# UFS0_HCLK_ECC_AGGR_CFG register map
Vendor: Texas Instruments
Peripheral module from a debugger description file (folder J7ES).
Registers are 32-bit, access not given, reset 0x0 unless marked. A register's access mark holds for its fields unless they carry their own. Offsets are as the file gives them; lines under a group give offsets from that group; [hi:lo] are bit positions; {n}, {i} and the like mark numbered series; 'fields as' and 'values as' point back to an identical list; <NAME> marks a mode.

## UFS0_HCLK_ECC_AGGR_CFG
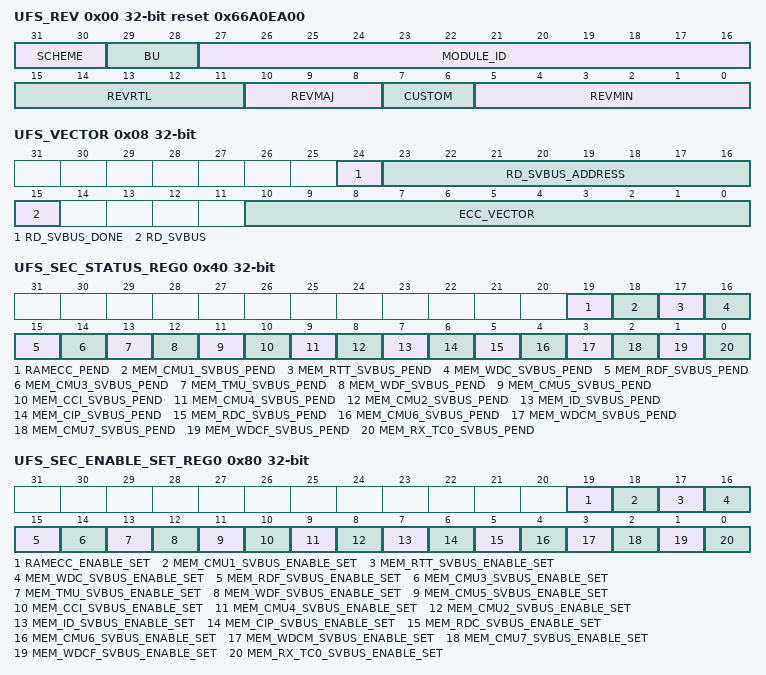
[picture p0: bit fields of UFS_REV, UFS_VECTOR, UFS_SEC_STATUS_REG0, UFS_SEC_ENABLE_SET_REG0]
0x00 UFS_REV ro reset 0x66A0EA00 — Aggregator Revision Register Revision parameters.
  [31:30] SCHEME
  [29:28] BU — Business Unit
  [27:16] MODULE_ID
  [15:11] REVRTL — RTL Version
  [10:8] REVMAJ — Major Version
  [7:6] CUSTOM — Custom Version
  [5:0] REVMIN — Minor Version
0x08 UFS_VECTOR — ECC Vector Register
  [24] RD_SVBUS_DONE — Read Done Status to indicate if read on the serial VBUS interface is complete, write of any value will clear this bit. (access RW1C)
  [23:16] RD_SVBUS_ADDRESS rw — Read Address
  [15] RD_SVBUS — Read Trigger Write 1h to trigger a read on the serial VBUS interface. (access RW1S)
  [10:0] ECC_VECTOR rw — ECC RAM ID Value written to select the corresponding ECC RAM for control or status.
0x0C UFS_STAT ro reset 0x14 — Misc Status Register
  [10:0] NUM_RAMS — Number of RAMs Indicates the number of RAMS serviced by the ECC Aggregator.
0x10 UFS_RESERVED_SVBUS_y rw — Reserved Area For Serial VBUS Registers Offset = 10h + (y × 4h); where y = 0h to 7h;
  [31:0] DATA — Serial VBUS Register Data
0x3C UFS_SEC_EOI_REG — SEC End Of Interrupt (EOI) Register The SEC End Of Interrupt (EOI) register is used to re-trigger the pulse interrupt signal to ensure that any nested interrupt events are serviced. The software interrupt handler must write to the SEC End Of Interrupt (EOI) register at the end of the current interrupt processing routine, so that new events can re-trigger the pulse interrupt signal again. For level interrupt signals the SEC End Of Interrupt (EOI) register is not functional and must not be used.
  [0] EOI_WR — End Of Interrupt (EOI) (access RW1S)
0x40 UFS_SEC_STATUS_REG0 — SEC Interrupt Status Register 0
  [19] RAMECC_PEND — Interrupt Pending Status for ramecc_pend (access RW1S)
  [18] MEM_CMU1_SVBUS_PEND — Interrupt Pending Status for mem_cmu1_svbus_pend (access RW1S)
  [17] MEM_RTT_SVBUS_PEND — Interrupt Pending Status for mem_rtt_svbus_pend (access RW1S)
  [16] MEM_WDC_SVBUS_PEND — Interrupt Pending Status for mem_wdc_svbus_pend (access RW1S)
  [15] MEM_RDF_SVBUS_PEND — Interrupt Pending Status for mem_rdf_svbus_pend (access RW1S)
  [14] MEM_CMU3_SVBUS_PEND — Interrupt Pending Status for mem_cmu3_svbus_pend (access RW1S)
  [13] MEM_TMU_SVBUS_PEND — Interrupt Pending Status for mem_tmu_svbus_pend (access RW1S)
  [12] MEM_WDF_SVBUS_PEND — Interrupt Pending Status for mem_wdf_svbus_pend (access RW1S)
  [11] MEM_CMU5_SVBUS_PEND — Interrupt Pending Status for mem_cmu5_svbus_pend (access RW1S)
  [10] MEM_CCI_SVBUS_PEND — Interrupt Pending Status for mem_cci_svbus_pend (access RW1S)
  [9] MEM_CMU4_SVBUS_PEND — Interrupt Pending Status for mem_cmu4_svbus_pend (access RW1S)
  [8] MEM_CMU2_SVBUS_PEND — Interrupt Pending Status for mem_cmu2_svbus_pend (access RW1S)
  [7] MEM_ID_SVBUS_PEND — Interrupt Pending Status for mem_id_svbus_pend (access RW1S)
  [6] MEM_CIP_SVBUS_PEND — Interrupt Pending Status for mem_cip_svbus_pend (access RW1S)
  [5] MEM_RDC_SVBUS_PEND — Interrupt Pending Status for mem_rdc_svbus_pend (access RW1S)
  [4] MEM_CMU6_SVBUS_PEND — Interrupt Pending Status for mem_cmu6_svbus_pend (access RW1S)
  [3] MEM_WDCM_SVBUS_PEND — Interrupt Pending Status for mem_wdcm_svbus_pend (access RW1S)
  [2] MEM_CMU7_SVBUS_PEND — Interrupt Pending Status for mem_cmu7_svbus_pend (access RW1S)
  [1] MEM_WDCF_SVBUS_PEND — Interrupt Pending Status for mem_wdcf_svbus_pend (access RW1S)
  [0] MEM_RX_TC0_SVBUS_PEND — Interrupt Pending Status for mem_rx_tc0_svbus_pend (access RW1S)
0x80 UFS_SEC_ENABLE_SET_REG0 — SEC Interrupt Enable Set Register 0
  [19] RAMECC_ENABLE_SET — Interrupt Enable Set for ramecc_pend (access RW1S)
  [18] MEM_CMU1_SVBUS_ENABLE_SET — Interrupt Enable Set for mem_cmu1_svbus_pend (access RW1S)
  [17] MEM_RTT_SVBUS_ENABLE_SET — Interrupt Enable Set for mem_rtt_svbus_pend (access RW1S)
  [16] MEM_WDC_SVBUS_ENABLE_SET — Interrupt Enable Set for mem_wdc_svbus_pend (access RW1S)
  [15] MEM_RDF_SVBUS_ENABLE_SET — Interrupt Enable Set for mem_rdf_svbus_pend (access RW1S)
  [14] MEM_CMU3_SVBUS_ENABLE_SET — Interrupt Enable Set for mem_cmu3_svbus_pend (access RW1S)
  [13] MEM_TMU_SVBUS_ENABLE_SET — Interrupt Enable Set for mem_tmu_svbus_pend (access RW1S)
  [12] MEM_WDF_SVBUS_ENABLE_SET — Interrupt Enable Set for mem_wdf_svbus_pend (access RW1S)
  [11] MEM_CMU5_SVBUS_ENABLE_SET — Interrupt Enable Set for mem_cmu5_svbus_pend (access RW1S)
  [10] MEM_CCI_SVBUS_ENABLE_SET — Interrupt Enable Set for mem_cci_svbus_pend (access RW1S)
  [9] MEM_CMU4_SVBUS_ENABLE_SET — Interrupt Enable Set for mem_cmu4_svbus_pend (access RW1S)
  [8] MEM_CMU2_SVBUS_ENABLE_SET — Interrupt Enable Set for mem_cmu2_svbus_pend (access RW1S)
  [7] MEM_ID_SVBUS_ENABLE_SET — Interrupt Enable Set for mem_id_svbus_pend (access RW1S)
  [6] MEM_CIP_SVBUS_ENABLE_SET — Interrupt Enable Set for mem_cip_svbus_pend (access RW1S)
  [5] MEM_RDC_SVBUS_ENABLE_SET — Interrupt Enable Set for mem_rdc_svbus_pend (access RW1S)
  [4] MEM_CMU6_SVBUS_ENABLE_SET — Interrupt Enable Set for mem_cmu6_svbus_pend (access RW1S)
  [3] MEM_WDCM_SVBUS_ENABLE_SET — Interrupt Enable Set for mem_wdcm_svbus_pend (access RW1S)
  [2] MEM_CMU7_SVBUS_ENABLE_SET — Interrupt Enable Set for mem_cmu7_svbus_pend (access RW1S)
  [1] MEM_WDCF_SVBUS_ENABLE_SET — Interrupt Enable Set for mem_wdcf_svbus_pend (access RW1S)
  [0] MEM_RX_TC0_SVBUS_ENABLE_SET — Interrupt Enable Set for mem_rx_tc0_svbus_pend (access RW1S)
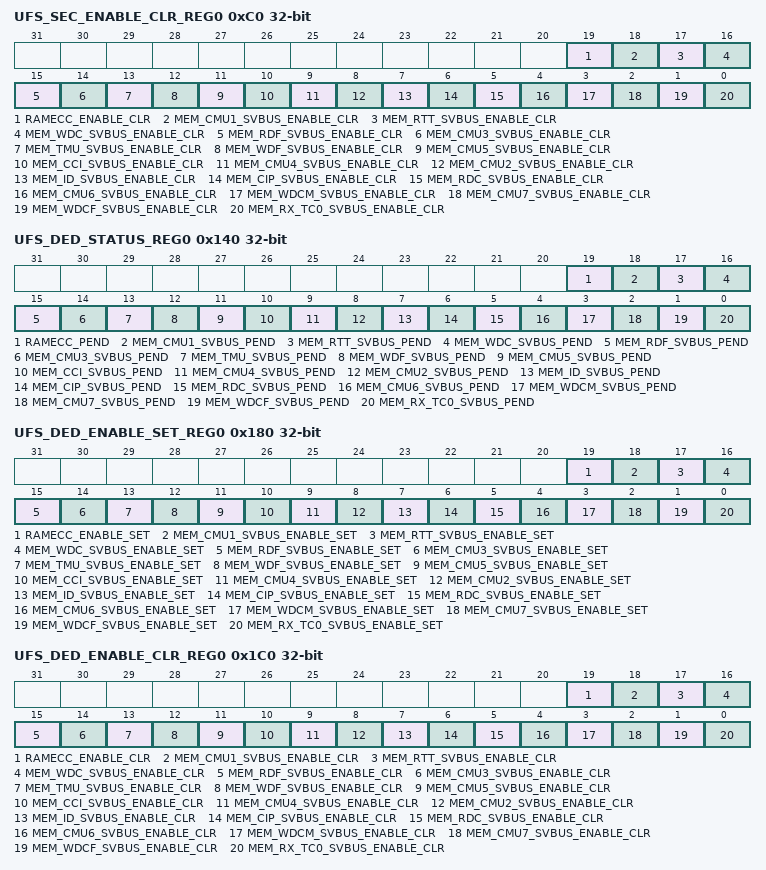
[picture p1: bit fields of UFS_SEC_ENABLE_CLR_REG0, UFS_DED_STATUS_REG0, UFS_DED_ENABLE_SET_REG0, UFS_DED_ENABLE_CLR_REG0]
0xC0 UFS_SEC_ENABLE_CLR_REG0 — SEC Interrupt Enable Clear Register 0
  [19] RAMECC_ENABLE_CLR — Interrupt Enable Clear for ramecc_pend (access RW1C)
  [18] MEM_CMU1_SVBUS_ENABLE_CLR — Interrupt Enable Clear for mem_cmu1_svbus_pend (access RW1C)
  [17] MEM_RTT_SVBUS_ENABLE_CLR — Interrupt Enable Clear for mem_rtt_svbus_pend (access RW1C)
  [16] MEM_WDC_SVBUS_ENABLE_CLR — Interrupt Enable Clear for mem_wdc_svbus_pend (access RW1C)
  [15] MEM_RDF_SVBUS_ENABLE_CLR — Interrupt Enable Clear for mem_rdf_svbus_pend (access RW1C)
  [14] MEM_CMU3_SVBUS_ENABLE_CLR — Interrupt Enable Clear for mem_cmu3_svbus_pend (access RW1C)
  [13] MEM_TMU_SVBUS_ENABLE_CLR — Interrupt Enable Clear for mem_tmu_svbus_pend (access RW1C)
  [12] MEM_WDF_SVBUS_ENABLE_CLR — Interrupt Enable Clear for mem_wdf_svbus_pend (access RW1C)
  [11] MEM_CMU5_SVBUS_ENABLE_CLR — Interrupt Enable Clear for mem_cmu5_svbus_pend (access RW1C)
  [10] MEM_CCI_SVBUS_ENABLE_CLR — Interrupt Enable Clear for mem_cci_svbus_pend (access RW1C)
  [9] MEM_CMU4_SVBUS_ENABLE_CLR — Interrupt Enable Clear for mem_cmu4_svbus_pend (access RW1C)
  [8] MEM_CMU2_SVBUS_ENABLE_CLR — Interrupt Enable Clear for mem_cmu2_svbus_pend (access RW1C)
  [7] MEM_ID_SVBUS_ENABLE_CLR — Interrupt Enable Clear for mem_id_svbus_pend (access RW1C)
  [6] MEM_CIP_SVBUS_ENABLE_CLR — Interrupt Enable Clear for mem_cip_svbus_pend (access RW1C)
  [5] MEM_RDC_SVBUS_ENABLE_CLR — Interrupt Enable Clear for mem_rdc_svbus_pend (access RW1C)
  [4] MEM_CMU6_SVBUS_ENABLE_CLR — Interrupt Enable Clear for mem_cmu6_svbus_pend (access RW1C)
  [3] MEM_WDCM_SVBUS_ENABLE_CLR — Interrupt Enable Clear for mem_wdcm_svbus_pend (access RW1C)
  [2] MEM_CMU7_SVBUS_ENABLE_CLR — Interrupt Enable Clear for mem_cmu7_svbus_pend (access RW1C)
  [1] MEM_WDCF_SVBUS_ENABLE_CLR — Interrupt Enable Clear for mem_wdcf_svbus_pend (access RW1C)
  [0] MEM_RX_TC0_SVBUS_ENABLE_CLR — Interrupt Enable Clear for mem_rx_tc0_svbus_pend (access RW1C)
0x13C UFS_DED_EOI_REG — DED End Of Interrupt (EOI) Register The DED End Of Interrupt (EOI) register is used to re-trigger the pulse interrupt signal to ensure that any nested interrupt events are serviced. The software interrupt handler must write to the DED End Of Interrupt (EOI) register at the end of the current interrupt processing routine, so that new events can re-trigger the pulse interrupt signal again. For level interrupt signals the DED End Of Interrupt (EOI) register is not functional and must not be used.
  [0] EOI_WR — End Of Interrupt (EOI) (access RW1S)
0x140 UFS_DED_STATUS_REG0 — DED Interrupt Status Register 0
  fields as UFS_SEC_STATUS_REG0
0x180 UFS_DED_ENABLE_SET_REG0 — DED Interrupt Enable Set Register 0
  fields as UFS_SEC_ENABLE_SET_REG0
0x1C0 UFS_DED_ENABLE_CLR_REG0 — DED Interrupt Enable Clear Register 0
  fields as UFS_SEC_ENABLE_CLR_REG0
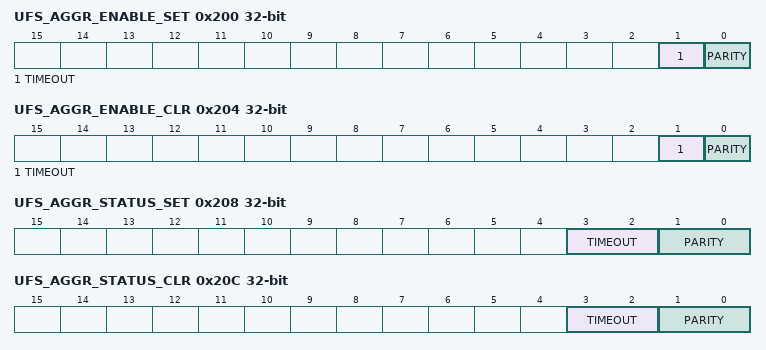
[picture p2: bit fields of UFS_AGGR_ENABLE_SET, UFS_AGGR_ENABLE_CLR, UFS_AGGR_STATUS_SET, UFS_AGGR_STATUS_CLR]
0x200 UFS_AGGR_ENABLE_SET — Aggregator Interrupt Enable Set Register
  [1] TIMEOUT — Interrupt enable set for serial VBUS timeout errors. (access RW1S)
  [0] PARITY — Interrupt enable set for parity errors. (access RW1S)
0x204 UFS_AGGR_ENABLE_CLR — Aggregator Interrupt Enable Clear Register
  [1] TIMEOUT — Interrupt enable clear for serial VBUS timeout errors. (access RW1C)
  [0] PARITY — Interrupt enable clear for parity errors. (access RW1C)
0x208 UFS_AGGR_STATUS_SET — Aggregator Interrupt Status Set Register
  [3:2] TIMEOUT — Interrupt status set for serial VBUS timeout errors. (access RWincr)
  [1:0] PARITY — Interrupt status set for parity errors. (access RWincr)
0x20C UFS_AGGR_STATUS_CLR — Aggregator Interrupt Status Clear Register
  [3:2] TIMEOUT — Interrupt status clear for serial VBUS timeout errors. (access RWdecr)
  [1:0] PARITY — Interrupt status clear for parity errors. (access RWdecr)
